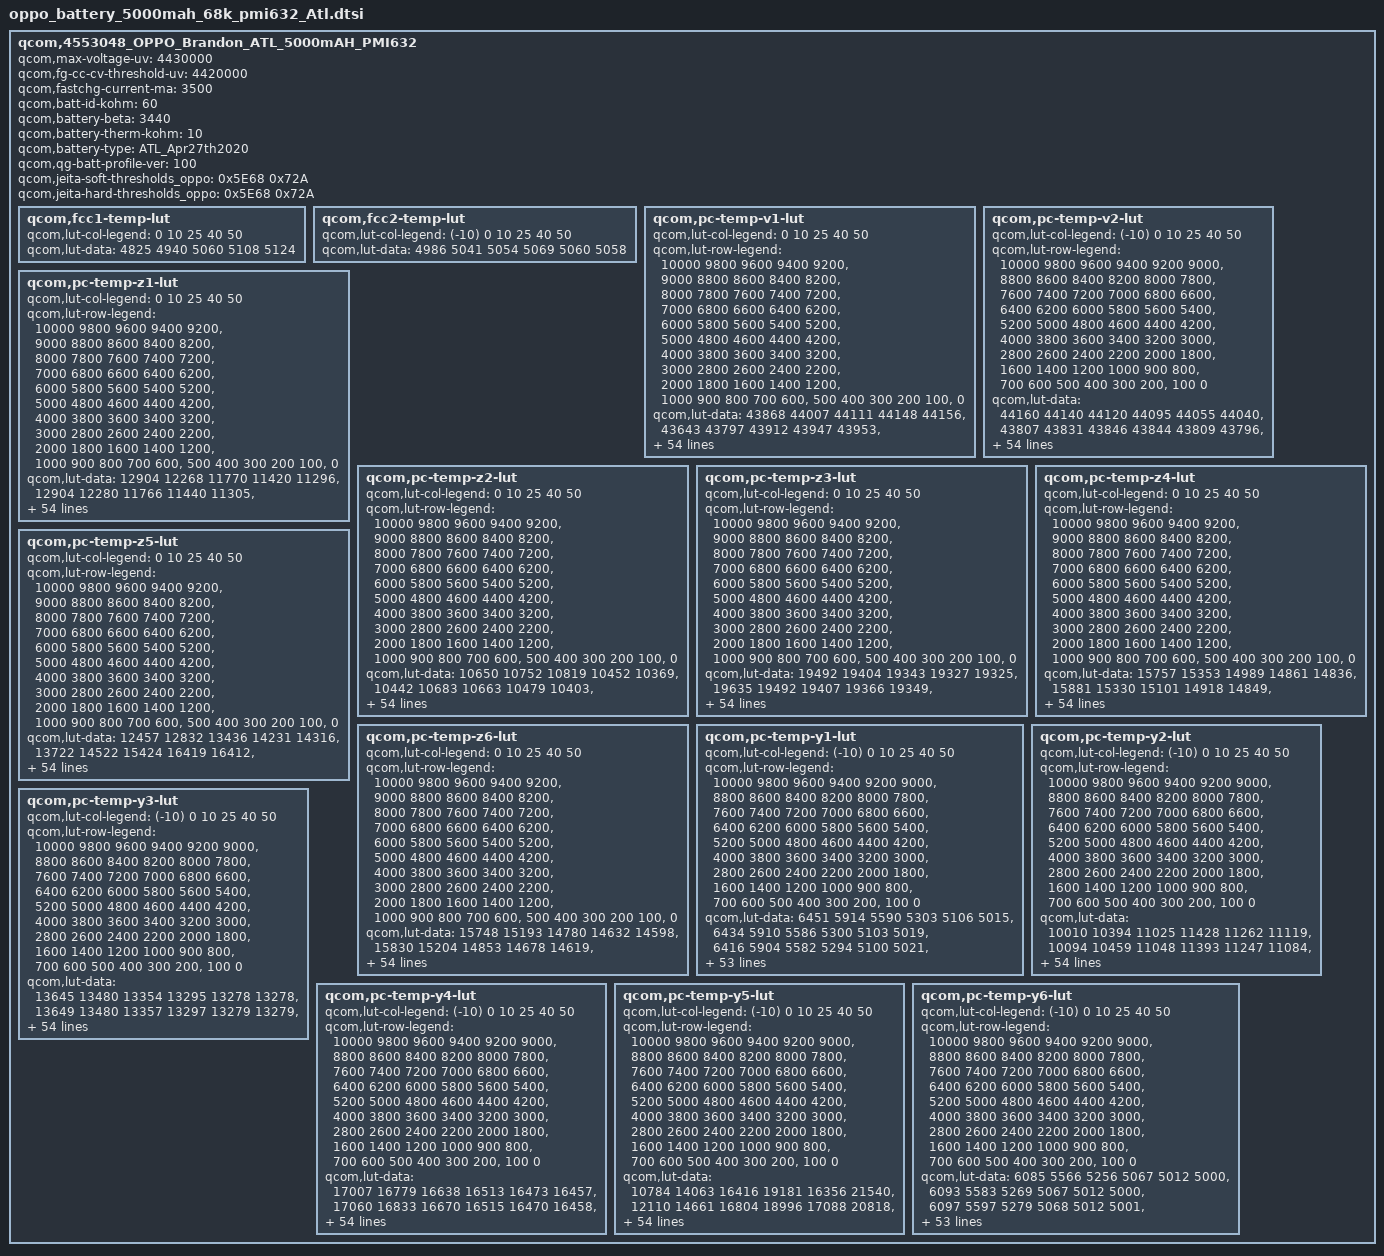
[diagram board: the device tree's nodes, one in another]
qcom,4553048_OPPO_Brandon_ATL_5000mAH_PMI632 {
    /* 4553048_OPPO_Brandon_ATL_5000mAH_PMI632_averaged_MasterSlave_Apr27th2020 */
    qcom,max-voltage-uv = <4430000>;
    qcom,fg-cc-cv-threshold-uv = <4420000>;
    qcom,fastchg-current-ma = <3500>;
    qcom,batt-id-kohm = <60>;
    qcom,battery-beta = <3440>;
    qcom,battery-therm-kohm = <10>;
    qcom,battery-type = "ATL_Apr27th2020";
    qcom,qg-batt-profile-ver = <100>;
    qcom,jeita-soft-thresholds_oppo = <0x5E68 0x72A>;
    qcom,jeita-hard-thresholds_oppo = <0x5E68 0x72A>;

	qcom,fcc1-temp-lut {
		qcom,lut-col-legend = <0 10 25 40 50>;
		qcom,lut-data = <4825 4940 5060 5108 5124>;
	};

	qcom,fcc2-temp-lut {
		qcom,lut-col-legend = <(-10) 0 10 25 40 50>;
		qcom,lut-data = <4986 5041 5054 5069 5060 5058>;
	};

	qcom,pc-temp-v1-lut {
		qcom,lut-col-legend = <0 10 25 40 50>;
		qcom,lut-row-legend = <10000 9800 9600 9400 9200>,
			<9000 8800 8600 8400 8200>,
			<8000 7800 7600 7400 7200>,
			<7000 6800 6600 6400 6200>,
			<6000 5800 5600 5400 5200>,
			<5000 4800 4600 4400 4200>,
			<4000 3800 3600 3400 3200>,
			<3000 2800 2600 2400 2200>,
			<2000 1800 1600 1400 1200>,
			<1000 900 800 700 600>,
			<500 400 300 200 100>,
			<0>;
		qcom,lut-data = <43868 44007 44111 44148 44156>,
			<43643 43797 43912 43947 43953>,
			<43414 43579 43711 43747 43756>,
			<43182 43353 43505 43541 43548>,
			<42950 43122 43280 43326 43332>,
			<42715 42887 43042 43100 43110>,
			<42481 42650 42806 42869 42881>,
			<42249 42412 42567 42633 42647>,
			<42019 42177 42328 42394 42408>,
			<41795 41944 42090 42156 42171>,
			<41575 41718 41855 41920 41935>,
			<41361 41497 41624 41687 41702>,
			<41154 41281 41397 41457 41474>,
			<40954 41074 41177 41231 41250>,
			<40754 40872 40966 41016 41031>,
			<40552 40672 40763 40809 40818>,
			<40355 40472 40566 40609 40614>,
			<40175 40282 40374 40416 40419>,
			<40006 40112 40189 40229 40232>,
			<39845 39954 40022 40053 40055>,
			<39696 39779 39850 39883 39887>,
			<39551 39580 39616 39679 39692>,
			<39396 39373 39314 39403 39430>,
			<39227 39151 39092 39159 39187>,
			<39061 38925 38966 39011 39034>,
			<38898 38781 38867 38896 38916>,
			<38744 38699 38771 38788 38803>,
			<38635 38634 38685 38687 38697>,
			<38562 38567 38602 38592 38596>,
			<38502 38503 38523 38497 38496>,
			<38446 38444 38449 38408 38402>,
			<38396 38386 38380 38329 38319>,
			<38351 38334 38316 38259 38246>,
			<38310 38288 38258 38194 38177>,
			<38273 38249 38207 38134 38110>,
			<38237 38209 38158 38077 38044>,
			<38205 38170 38111 38019 37978>,
			<38166 38126 38066 37963 37912>,
			<38101 38058 38003 37893 37833>,
			<38009 37959 37906 37798 37733>,
			<37905 37848 37791 37687 37619>,
			<37778 37727 37669 37571 37497>,
			<37634 37589 37530 37440 37363>,
			<37469 37418 37365 37280 37203>,
			<37329 37267 37213 37134 37064>,
			<37223 37158 37112 37044 36984>,
			<37192 37129 37080 37015 36954>,
			<37153 37101 37063 36994 36936>,
			<37118 37074 37039 36975 36914>,
			<37075 37041 36987 36913 36841>,
			<36884 36827 36746 36645 36555>,
			<36449 36405 36310 36205 36111>,
			<35872 35837 35735 35629 35536>,
			<35083 35057 34953 34849 34754>,
			<33802 33828 33739 33636 33535>,
			<30000 30000 30000 30000 30000>;
	};

	qcom,pc-temp-v2-lut {
		qcom,lut-col-legend = <(-10) 0 10 25 40 50>;
		qcom,lut-row-legend = <10000 9800 9600 9400 9200 9000>,
			<8800 8600 8400 8200 8000 7800>,
			<7600 7400 7200 7000 6800 6600>,
			<6400 6200 6000 5800 5600 5400>,
			<5200 5000 4800 4600 4400 4200>,
			<4000 3800 3600 3400 3200 3000>,
			<2800 2600 2400 2200 2000 1800>,
			<1600 1400 1200 1000 900 800>,
			<700 600 500 400 300 200>,
			<100 0>;
		qcom,lut-data = <44160 44140 44120 44095 44055 44040>,
			<43807 43831 43846 43844 43809 43796>,
			<43484 43544 43585 43602 43571 43560>,
			<43198 43283 43339 43369 43341 43331>,
			<42946 43046 43112 43146 43120 43111>,
			<42700 42811 42881 42920 42895 42887>,
			<42448 42567 42639 42684 42661 42654>,
			<42197 42322 42394 42444 42422 42417>,
			<41941 42078 42151 42206 42185 42181>,
			<41674 41834 41907 41966 41948 41944>,
			<41442 41589 41670 41731 41715 41711>,
			<41283 41323 41439 41499 41484 41481>,
			<41140 41074 41215 41272 41258 41255>,
			<40915 40906 41001 41052 41040 41036>,
			<40554 40788 40794 40837 40826 40820>,
			<40203 40633 40589 40630 40621 40614>,
			<39934 40355 40388 40428 40422 40416>,
			<39695 40034 40185 40233 40230 40225>,
			<39474 39780 39963 40050 40049 40045>,
			<39271 39557 39725 39874 39874 39874>,
			<39078 39341 39493 39671 39676 39679>,
			<38882 39125 39265 39408 39422 39431>,
			<38698 38916 39053 39154 39174 39186>,
			<38554 38713 38872 38967 38989 39001>,
			<38438 38514 38713 38809 38832 38843>,
			<38342 38360 38570 38672 38697 38707>,
			<38265 38242 38442 38552 38579 38588>,
			<38200 38148 38324 38443 38473 38481>,
			<38136 38083 38206 38341 38376 38381>,
			<38074 38033 38094 38246 38286 38288>,
			<38014 37984 38005 38159 38204 38204>,
			<37954 37936 37935 38080 38130 38129>,
			<37895 37888 37878 38006 38058 38055>,
			<37834 37839 37836 37936 37985 37980>,
			<37773 37789 37803 37868 37911 37902>,
			<37708 37737 37763 37797 37825 37808>,
			<37639 37681 37721 37723 37723 37691>,
			<37564 37620 37670 37646 37619 37576>,
			<37484 37547 37599 37569 37525 37481>,
			<37395 37463 37509 37488 37434 37391>,
			<37305 37369 37406 37400 37342 37298>,
			<37218 37260 37282 37301 37250 37203>,
			<37133 37134 37145 37178 37134 37082>,
			<37051 36986 36994 37038 36996 36941>,
			<36971 36848 36851 36914 36891 36836>,
			<36888 36757 36752 36858 36846 36799>,
			<36838 36723 36720 36837 36836 36787>,
			<36788 36690 36679 36816 36821 36771>,
			<36733 36652 36626 36777 36790 36740>,
			<36662 36590 36527 36687 36702 36639>,
			<36546 36408 36317 36409 36390 36292>,
			<36325 35982 35880 35894 35895 35798>,
			<35918 35316 35265 35236 35256 35147>,
			<35251 34296 34378 34296 34368 34253>,
			<34202 32520 32883 32955 33025 32854>,
			<32670 29515 29418 28130 28230 28273>;
	};

	qcom,pc-temp-z1-lut {
		qcom,lut-col-legend = <0 10 25 40 50>;
		qcom,lut-row-legend = <10000 9800 9600 9400 9200>,
			<9000 8800 8600 8400 8200>,
			<8000 7800 7600 7400 7200>,
			<7000 6800 6600 6400 6200>,
			<6000 5800 5600 5400 5200>,
			<5000 4800 4600 4400 4200>,
			<4000 3800 3600 3400 3200>,
			<3000 2800 2600 2400 2200>,
			<2000 1800 1600 1400 1200>,
			<1000 900 800 700 600>,
			<500 400 300 200 100>,
			<0>;
		qcom,lut-data = <12904 12268 11770 11420 11296>,
			<12904 12280 11766 11440 11305>,
			<12913 12283 11759 11435 11305>,
			<12924 12277 11751 11427 11304>,
			<12924 12267 11744 11420 11302>,
			<12922 12254 11734 11413 11298>,
			<12919 12236 11725 11407 11294>,
			<12904 12219 11715 11401 11291>,
			<12879 12210 11706 11395 11289>,
			<12862 12202 11695 11392 11289>,
			<12846 12193 11686 11390 11289>,
			<12832 12178 11684 11389 11289>,
			<12820 12168 11684 11389 11289>,
			<12803 12165 11684 11389 11289>,
			<12795 12161 11685 11389 11290>,
			<12799 12160 11685 11389 11290>,
			<12803 12159 11685 11390 11291>,
			<12797 12158 11683 11391 11293>,
			<12779 12157 11683 11393 11295>,
			<12762 12157 11686 11395 11297>,
			<12749 12160 11690 11397 11298>,
			<12738 12169 11692 11398 11299>,
			<12738 12178 11696 11400 11300>,
			<12756 12183 11698 11401 11301>,
			<12772 12191 11699 11403 11303>,
			<12779 12193 11702 11406 11307>,
			<12785 12192 11705 11409 11310>,
			<12786 12190 11710 11413 11313>,
			<12787 12193 11714 11417 11316>,
			<12790 12198 11717 11421 11320>,
			<12794 12201 11720 11424 11324>,
			<12798 12202 11725 11428 11328>,
			<12801 12203 11732 11434 11332>,
			<12805 12207 11737 11440 11335>,
			<12808 12215 11740 11444 11340>,
			<12812 12221 11743 11448 11344>,
			<12826 12225 11748 11452 11348>,
			<12837 12229 11754 11456 11352>,
			<12847 12234 11761 11460 11355>,
			<12864 12241 11770 11465 11359>,
			<12876 12250 11778 11470 11362>,
			<12900 12268 11785 11474 11365>,
			<12908 12282 11793 11479 11368>,
			<12891 12293 11807 11484 11371>,
			<12890 12294 11819 11491 11375>,
			<12898 12297 11827 11495 11378>,
			<12908 12281 11819 11496 11378>,
			<12953 12277 11818 11497 11379>,
			<12948 12285 11832 11499 11381>,
			<12908 12298 11842 11504 11385>,
			<12950 12304 11842 11511 11390>,
			<12955 12334 11849 11518 11396>,
			<12986 12338 11866 11530 11405>,
			<13023 12383 11891 11546 11418>,
			<13023 12383 11891 11546 11418>,
			<13023 12383 11891 11546 11418>;
	};

	qcom,pc-temp-z2-lut {
		qcom,lut-col-legend = <0 10 25 40 50>;
		qcom,lut-row-legend = <10000 9800 9600 9400 9200>,
			<9000 8800 8600 8400 8200>,
			<8000 7800 7600 7400 7200>,
			<7000 6800 6600 6400 6200>,
			<6000 5800 5600 5400 5200>,
			<5000 4800 4600 4400 4200>,
			<4000 3800 3600 3400 3200>,
			<3000 2800 2600 2400 2200>,
			<2000 1800 1600 1400 1200>,
			<1000 900 800 700 600>,
			<500 400 300 200 100>,
			<0>;
		qcom,lut-data = <10650 10752 10819 10452 10369>,
			<10442 10683 10663 10479 10403>,
			<10412 10628 11155 10533 10433>,
			<10395 10586 11549 10610 10535>,
			<10375 10550 11287 10623 10569>,
			<10355 10518 10768 10594 10548>,
			<10341 10488 10600 10559 10521>,
			<10332 10463 10559 10522 10487>,
			<10325 10443 10533 10487 10440>,
			<10321 10426 10514 10473 10416>,
			<10318 10424 10501 10461 10402>,
			<10316 10426 10501 10457 10396>,
			<10318 10429 10513 10460 10403>,
			<10323 10447 10531 10462 10411>,
			<10325 10478 10713 10448 10405>,
			<10323 10502 10966 10414 10377>,
			<10321 10517 10958 10389 10363>,
			<10327 10533 10728 10371 10349>,
			<10351 10552 10603 10361 10333>,
			<10377 10571 10615 10370 10341>,
			<10403 10589 10637 10403 10360>,
			<10429 10609 10679 10451 10386>,
			<10443 10623 10754 10553 10458>,
			<10451 10628 10785 10624 10521>,
			<10458 10631 10709 10574 10522>,
			<10471 10632 10620 10477 10508>,
			<10486 10622 10624 10462 10497>,
			<10496 10612 10668 10514 10488>,
			<10502 10613 10705 10570 10484>,
			<10508 10620 10734 10637 10513>,
			<10514 10628 10753 10707 10564>,
			<10522 10639 10751 10705 10557>,
			<10530 10649 10744 10652 10469>,
			<10538 10654 10740 10618 10401>,
			<10547 10657 10740 10613 10375>,
			<10557 10660 10742 10613 10358>,
			<10568 10667 10743 10629 10373>,
			<10581 10677 10748 10672 10438>,
			<10594 10689 10758 10713 10498>,
			<10608 10706 10799 10754 10545>,
			<10623 10716 10833 10782 10581>,
			<10638 10720 10834 10779 10604>,
			<10665 10724 10826 10767 10626>,
			<10730 10746 10814 10777 10681>,
			<10550 10932 10859 10758 10674>,
			<10719 11035 10907 10682 10533>,
			<10241 11044 10900 10638 10522>,
			<10297 11066 10865 10612 10539>,
			<10363 11095 10853 10646 10577>,
			<10048 11232 10908 10779 10672>,
			<10110 11153 11011 10653 10508>,
			<9758 11095 10931 10499 10307>,
			<9832 10908 10879 10394 10249>,
			<9855 10664 10796 10386 10193>,
			<9855 10664 10796 10386 10193>,
			<9855 10664 10796 10386 10193>;
	};

	qcom,pc-temp-z3-lut {
		qcom,lut-col-legend = <0 10 25 40 50>;
		qcom,lut-row-legend = <10000 9800 9600 9400 9200>,
			<9000 8800 8600 8400 8200>,
			<8000 7800 7600 7400 7200>,
			<7000 6800 6600 6400 6200>,
			<6000 5800 5600 5400 5200>,
			<5000 4800 4600 4400 4200>,
			<4000 3800 3600 3400 3200>,
			<3000 2800 2600 2400 2200>,
			<2000 1800 1600 1400 1200>,
			<1000 900 800 700 600>,
			<500 400 300 200 100>,
			<0>;
		qcom,lut-data = <19492 19404 19343 19327 19325>,
			<19635 19492 19407 19366 19349>,
			<19704 19548 19428 19384 19362>,
			<19746 19578 19440 19397 19382>,
			<19762 19596 19454 19406 19394>,
			<19771 19600 19466 19413 19400>,
			<19776 19600 19469 19417 19403>,
			<19777 19600 19467 19418 19405>,
			<19778 19599 19465 19418 19406>,
			<19776 19596 19464 19416 19406>,
			<19769 19591 19462 19409 19401>,
			<19760 19582 19458 19404 19396>,
			<19750 19571 19450 19401 19391>,
			<19737 19560 19445 19398 19387>,
			<19733 19550 19447 19393 19383>,
			<19741 19546 19452 19383 19379>,
			<19749 19544 19448 19377 19375>,
			<19743 19543 19434 19373 19371>,
			<19719 19539 19426 19370 19368>,
			<19701 19531 19424 19368 19363>,
			<19695 19530 19423 19365 19356>,
			<19691 19542 19427 19366 19354>,
			<19693 19555 19442 19372 19355>,
			<19708 19559 19449 19378 19357>,
			<19721 19562 19436 19370 19350>,
			<19723 19562 19420 19354 19336>,
			<19724 19555 19418 19350 19333>,
			<19724 19547 19417 19352 19344>,
			<19716 19544 19417 19355 19358>,
			<19705 19542 19425 19373 19374>,
			<19697 19542 19435 19396 19390>,
			<19691 19543 19439 19399 19392>,
			<19686 19545 19443 19398 19385>,
			<19681 19545 19444 19395 19376>,
			<19675 19542 19441 19389 19368>,
			<19668 19539 19437 19382 19361>,
			<19658 19537 19432 19376 19355>,
			<19649 19535 19426 19371 19351>,
			<19645 19532 19422 19367 19348>,
			<19642 19528 19420 19365 19346>,
			<19636 19524 19418 19363 19344>,
			<19625 19517 19416 19363 19346>,
			<19609 19509 19413 19363 19353>,
			<19587 19499 19408 19363 19357>,
			<19424 19460 19395 19361 19357>,
			<19366 19440 19384 19346 19338>,
			<19295 19424 19384 19344 19336>,
			<19297 19422 19375 19342 19330>,
			<19310 19411 19375 19334 19322>,
			<19267 19311 19368 19326 19321>,
			<19287 19402 19360 19345 19348>,
			<19274 19322 19360 19361 19358>,
			<19302 19309 19366 19365 19359>,
			<19339 19312 19363 19353 19352>,
			<19339 19312 19363 19353 19352>,
			<19339 19312 19363 19353 19352>;
	};

	qcom,pc-temp-z4-lut {
		qcom,lut-col-legend = <0 10 25 40 50>;
		qcom,lut-row-legend = <10000 9800 9600 9400 9200>,
			<9000 8800 8600 8400 8200>,
			<8000 7800 7600 7400 7200>,
			<7000 6800 6600 6400 6200>,
			<6000 5800 5600 5400 5200>,
			<5000 4800 4600 4400 4200>,
			<4000 3800 3600 3400 3200>,
			<3000 2800 2600 2400 2200>,
			<2000 1800 1600 1400 1200>,
			<1000 900 800 700 600>,
			<500 400 300 200 100>,
			<0>;
		qcom,lut-data = <15757 15353 14989 14861 14836>,
			<15881 15330 15101 14918 14849>,
			<15776 15292 15049 14908 14852>,
			<15611 15216 14987 14875 14834>,
			<15484 15113 14945 14846 14814>,
			<15368 15037 14907 14819 14793>,
			<15270 14978 14872 14795 14773>,
			<15189 14929 14842 14774 14755>,
			<15120 14890 14815 14756 14739>,
			<15065 14857 14790 14740 14726>,
			<15020 14832 14768 14726 14714>,
			<14983 14812 14752 14716 14706>,
			<14955 14795 14740 14708 14700>,
			<14931 14778 14729 14702 14696>,
			<14906 14763 14710 14699 14692>,
			<14873 14755 14691 14698 14687>,
			<14848 14752 14690 14695 14683>,
			<14841 14749 14700 14690 14679>,
			<14839 14741 14705 14685 14675>,
			<14835 14732 14702 14683 14675>,
			<14815 14730 14699 14681 14676>,
			<14789 14737 14718 14687 14680>,
			<14782 14749 14788 14746 14735>,
			<14781 14781 14829 14800 14792>,
			<14781 14834 14838 14812 14802>,
			<14795 14852 14842 14819 14808>,
			<14823 14842 14838 14818 14806>,
			<14832 14827 14823 14804 14783>,
			<14830 14815 14805 14784 14752>,
			<14826 14803 14785 14754 14723>,
			<14821 14791 14764 14719 14695>,
			<14813 14780 14749 14703 14685>,
			<14805 14769 14737 14694 14680>,
			<14798 14761 14731 14690 14678>,
			<14791 14755 14728 14690 14678>,
			<14784 14749 14726 14690 14679>,
			<14777 14744 14725 14691 14680>,
			<14770 14740 14724 14692 14682>,
			<14761 14739 14724 14695 14684>,
			<14752 14740 14729 14705 14696>,
			<14748 14740 14732 14714 14707>,
			<14746 14732 14726 14711 14703>,
			<14743 14721 14714 14703 14693>,
			<14734 14713 14710 14700 14691>,
			<14817 14694 14694 14690 14683>,
			<14845 14681 14671 14674 14671>,
			<14921 14689 14663 14668 14666>,
			<14917 14685 14657 14656 14657>,
			<14901 14689 14645 14644 14642>,
			<14933 14796 14649 14646 14635>,
			<14912 14698 14674 14659 14649>,
			<14946 14799 14683 14654 14652>,
			<14932 14818 14679 14655 14655>,
			<14917 14823 14683 14669 14664>,
			<14917 14823 14683 14669 14664>,
			<14917 14823 14683 14669 14664>;
	};

	qcom,pc-temp-z5-lut {
		qcom,lut-col-legend = <0 10 25 40 50>;
		qcom,lut-row-legend = <10000 9800 9600 9400 9200>,
			<9000 8800 8600 8400 8200>,
			<8000 7800 7600 7400 7200>,
			<7000 6800 6600 6400 6200>,
			<6000 5800 5600 5400 5200>,
			<5000 4800 4600 4400 4200>,
			<4000 3800 3600 3400 3200>,
			<3000 2800 2600 2400 2200>,
			<2000 1800 1600 1400 1200>,
			<1000 900 800 700 600>,
			<500 400 300 200 100>,
			<0>;
		qcom,lut-data = <12457 12832 13436 14231 14316>,
			<13722 14522 15424 16419 16412>,
			<14431 15830 16066 17472 17161>,
			<14960 16749 16480 18406 19269>,
			<15398 17487 17256 19214 20710>,
			<15744 18149 18320 19965 21471>,
			<16110 18723 18835 20465 22167>,
			<16629 19326 19168 21016 23054>,
			<17224 20135 19560 21622 23972>,
			<17706 20949 20202 21855 24728>,
			<18184 21424 21058 22278 25546>,
			<18537 21742 21833 22696 26067>,
			<18744 22097 22522 23609 26196>,
			<19024 22671 23412 24546 26297>,
			<19549 23454 26108 24259 26649>,
			<21824 24406 29215 23041 27570>,
			<24082 25915 29348 22558 28509>,
			<24020 27137 27804 23134 29650>,
			<22984 27309 26954 23975 30595>,
			<22416 27215 27729 24660 30365>,
			<23460 28531 29503 25444 29357>,
			<25809 38077 33729 26585 28946>,
			<29642 46694 42928 28960 28157>,
			<38348 47241 46951 30601 26763>,
			<45826 46715 38496 27205 23439>,
			<48858 45394 27802 20479 18180>,
			<51050 39805 24895 18241 16777>,
			<51318 34243 23492 17657 17149>,
			<47477 32754 23157 17444 17859>,
			<42755 31934 24582 19959 21416>,
			<40477 31796 27023 24655 26980>,
			<38863 33589 30015 28008 28953>,
			<37893 36054 33925 30892 29733>,
			<37303 37486 36831 32473 30040>,
			<36728 38573 39125 33153 29790>,
			<35886 39613 40441 33552 29360>,
			<34286 40906 39876 33359 29126>,
			<33292 41874 38170 32420 28800>,
			<34413 41930 36661 31222 28233>,
			<36481 41725 35255 29319 25967>,
			<36843 41334 34025 27354 23803>,
			<34563 38661 33209 25997 24014>,
			<32580 35994 32354 25112 25061>,
			<30816 35130 30226 25453 26961>,
			<21517 32333 30177 25797 27840>,
			<16113 31277 30542 23094 22090>,
			<12460 24700 31543 22984 21412>,
			<12455 23766 27667 24259 20815>,
			<12607 22019 29841 23744 22512>,
			<11939 13240 26835 21495 23364>,
			<12308 20595 20910 22182 26315>,
			<11953 13391 18851 24243 25270>,
			<12217 12728 19184 23646 22851>,
			<12515 12605 18363 18160 18332>,
			<12515 12605 18363 18160 18332>,
			<12515 12605 18363 18160 18332>;
	};

	qcom,pc-temp-z6-lut {
		qcom,lut-col-legend = <0 10 25 40 50>;
		qcom,lut-row-legend = <10000 9800 9600 9400 9200>,
			<9000 8800 8600 8400 8200>,
			<8000 7800 7600 7400 7200>,
			<7000 6800 6600 6400 6200>,
			<6000 5800 5600 5400 5200>,
			<5000 4800 4600 4400 4200>,
			<4000 3800 3600 3400 3200>,
			<3000 2800 2600 2400 2200>,
			<2000 1800 1600 1400 1200>,
			<1000 900 800 700 600>,
			<500 400 300 200 100>,
			<0>;
		qcom,lut-data = <15748 15193 14780 14632 14598>,
			<15830 15204 14853 14678 14619>,
			<15782 15203 14837 14678 14625>,
			<15704 15173 14818 14673 14628>,
			<15637 15119 14803 14667 14628>,
			<15570 15077 14788 14658 14622>,
			<15509 15041 14772 14649 14615>,
			<15460 15009 14755 14640 14608>,
			<15416 14983 14739 14631 14602>,
			<15378 14961 14726 14622 14596>,
			<15346 14940 14713 14613 14588>,
			<15317 14920 14702 14605 14582>,
			<15291 14903 14692 14600 14576>,
			<15268 14888 14684 14596 14572>,
			<15249 14874 14678 14591 14567>,
			<15234 14867 14673 14585 14563>,
			<15221 14863 14669 14580 14559>,
			<15206 14860 14666 14576 14555>,
			<15190 14854 14663 14572 14552>,
			<15176 14847 14662 14570 14548>,
			<15161 14846 14660 14568 14546>,
			<15148 14855 14671 14571 14546>,
			<15147 14870 14711 14602 14572>,
			<15155 14890 14731 14627 14597>,
			<15166 14916 14729 14626 14597>,
			<15178 14924 14724 14624 14594>,
			<15191 14917 14720 14621 14591>,
			<15195 14908 14714 14616 14587>,
			<15192 14902 14710 14612 14583>,
			<15187 14898 14706 14609 14580>,
			<15183 14895 14703 14606 14578>,
			<15178 14892 14700 14603 14574>,
			<15174 14889 14698 14599 14569>,
			<15171 14887 14696 14595 14564>,
			<15169 14884 14695 14592 14560>,
			<15165 14883 14693 14589 14557>,
			<15160 14883 14691 14587 14555>,
			<15158 14883 14689 14586 14554>,
			<15159 14884 14689 14585 14553>,
			<15162 14888 14692 14589 14557>,
			<15164 14889 14694 14593 14561>,
			<15166 14888 14693 14591 14561>,
			<15167 14885 14689 14588 14561>,
			<15164 14884 14687 14588 14562>,
			<15133 14868 14679 14584 14560>,
			<15122 14857 14666 14570 14545>,
			<15121 14853 14663 14567 14542>,
			<15120 14852 14657 14560 14534>,
			<15122 14850 14653 14551 14524>,
			<15124 14849 14653 14549 14521>,
			<15132 14860 14664 14566 14542>,
			<15148 14869 14670 14574 14551>,
			<15169 14879 14677 14579 14556>,
			<15200 14897 14683 14583 14559>,
			<15200 14897 14683 14583 14559>,
			<15200 14897 14683 14583 14559>;
	};

	qcom,pc-temp-y1-lut {
		qcom,lut-col-legend = <(-10) 0 10 25 40 50>;
		qcom,lut-row-legend = <10000 9800 9600 9400 9200 9000>,
			<8800 8600 8400 8200 8000 7800>,
			<7600 7400 7200 7000 6800 6600>,
			<6400 6200 6000 5800 5600 5400>,
			<5200 5000 4800 4600 4400 4200>,
			<4000 3800 3600 3400 3200 3000>,
			<2800 2600 2400 2200 2000 1800>,
			<1600 1400 1200 1000 900 800>,
			<700 600 500 400 300 200>,
			<100 0>;
		qcom,lut-data = <6451 5914 5590 5303 5106 5015>,
			<6434 5910 5586 5300 5103 5019>,
			<6416 5904 5582 5294 5100 5021>,
			<6400 5897 5577 5287 5098 5023>,
			<6389 5892 5574 5282 5095 5023>,
			<6386 5890 5571 5279 5093 5024>,
			<6390 5891 5569 5279 5091 5022>,
			<6397 5892 5567 5278 5090 5020>,
			<6404 5891 5567 5277 5088 5019>,
			<6415 5888 5569 5273 5086 5019>,
			<6423 5886 5569 5271 5084 5019>,
			<6424 5899 5564 5271 5083 5018>,
			<6422 5915 5557 5271 5082 5017>,
			<6418 5916 5561 5269 5081 5017>,
			<6405 5907 5575 5265 5081 5017>,
			<6396 5903 5581 5264 5081 5017>,
			<6395 5913 5576 5264 5081 5017>,
			<6396 5923 5570 5265 5081 5018>,
			<6398 5922 5567 5265 5082 5018>,
			<6410 5914 5565 5266 5083 5019>,
			<6422 5910 5565 5267 5084 5019>,
			<6432 5911 5570 5269 5085 5020>,
			<6444 5914 5575 5272 5086 5021>,
			<6445 5918 5575 5274 5087 5022>,
			<6435 5928 5573 5276 5089 5025>,
			<6428 5931 5574 5279 5092 5027>,
			<6435 5928 5577 5286 5094 5029>,
			<6450 5923 5582 5292 5096 5031>,
			<6450 5918 5585 5295 5098 5033>,
			<6425 5910 5590 5297 5100 5034>,
			<6406 5908 5591 5299 5102 5036>,
			<6410 5919 5593 5302 5107 5039>,
			<6420 5929 5596 5306 5112 5042>,
			<6419 5928 5596 5309 5116 5045>,
			<6404 5922 5596 5312 5120 5047>,
			<6392 5921 5596 5315 5123 5049>,
			<6396 5927 5597 5317 5126 5051>,
			<6405 5933 5599 5319 5128 5052>,
			<6409 5937 5600 5323 5130 5054>,
			<6411 5942 5602 5327 5131 5056>,
			<6411 5942 5605 5335 5133 5057>,
			<6415 5932 5616 5347 5135 5058>,
			<6419 5929 5618 5347 5137 5060>,
			<6422 5941 5610 5344 5138 5062>,
			<6438 5962 5612 5355 5141 5066>,
			<6439 5965 5626 5352 5144 5067>,
			<6487 5974 5625 5355 5146 5067>,
			<6494 5976 5623 5356 5144 5066>,
			<6498 5976 5629 5359 5145 5067>,
			<6518 6012 5646 5363 5146 5067>,
			<6603 6030 5661 5369 5145 5069>,
			<6668 6065 5666 5386 5152 5074>,
			<6738 6135 5720 5405 5158 5080>,
			<6848 6237 5756 5416 5171 5089>,
			<6848 6237 5756 5416 5171 5089>,
			<6848 6237 5756 5416 5171 5089>;
	};

	qcom,pc-temp-y2-lut {
		qcom,lut-col-legend = <(-10) 0 10 25 40 50>;
		qcom,lut-row-legend = <10000 9800 9600 9400 9200 9000>,
			<8800 8600 8400 8200 8000 7800>,
			<7600 7400 7200 7000 6800 6600>,
			<6400 6200 6000 5800 5600 5400>,
			<5200 5000 4800 4600 4400 4200>,
			<4000 3800 3600 3400 3200 3000>,
			<2800 2600 2400 2200 2000 1800>,
			<1600 1400 1200 1000 900 800>,
			<700 600 500 400 300 200>,
			<100 0>;
		qcom,lut-data = <10010 10394 11025 11428 11262 11119>,
			<10094 10459 11048 11393 11247 11084>,
			<10174 10528 11065 11358 11195 11049>,
			<10248 10593 11076 11326 11130 11015>,
			<10314 10648 11082 11297 11072 10984>,
			<10369 10685 11083 11274 11042 10956>,
			<10407 10711 11072 11257 11021 10927>,
			<10442 10728 11056 11241 11002 10903>,
			<10520 10724 11050 11223 11014 10893>,
			<10698 10696 11046 11203 11057 10886>,
			<10807 10683 11045 11195 11077 10884>,
			<10791 10797 11047 11205 11044 10875>,
			<10745 10945 11052 11221 11004 10864>,
			<10598 10955 11082 11235 11010 10869>,
			<10068 10919 11179 11251 11049 10892>,
			<9706 10903 11260 11274 11087 10914>,
			<9691 10980 11316 11320 11143 10934>,
			<9685 11091 11355 11382 11213 10961>,
			<9680 11151 11369 11465 11289 11038>,
			<9677 11195 11378 11566 11380 11192>,
			<9675 11209 11379 11594 11409 11250>,
			<9673 11186 11366 11535 11373 11230>,
			<9672 11136 11354 11475 11331 11207>,
			<9671 10963 11367 11470 11308 11198>,
			<9670 10550 11403 11477 11277 11192>,
			<9669 10291 11421 11490 11273 11200>,
			<9668 9993 11426 11525 11345 11228>,
			<9667 9729 11428 11565 11421 11266>,
			<9666 9700 11418 11592 11441 11315>,
			<9666 9692 11391 11617 11455 11376>,
			<9666 9687 11367 11647 11476 11398>,
			<9665 9682 11345 11685 11523 11392>,
			<9665 9678 11318 11707 11565 11389>,
			<9664 9674 11272 11685 11597 11451>,
			<9664 9670 11204 11646 11631 11559>,
			<9664 9668 11133 11636 11633 11570>,
			<9664 9666 11065 11636 11585 11449>,
			<9663 9665 10962 11634 11530 11350>,
			<9663 9663 10591 11605 11486 11340>,
			<9662 9662 10028 11553 11449 11346>,
			<9662 9662 9804 11510 11447 11360>,
			<9662 9661 9728 11470 11469 11393>,
			<9662 9661 9696 11404 11458 11358>,
			<9661 9660 9683 11315 11395 11219>,
			<9660 9659 9675 11258 11331 11186>,
			<9659 9659 9672 11243 11150 11017>,
			<9659 9658 9669 11201 11231 10988>,
			<9658 9658 9667 11172 11241 11060>,
			<9656 9657 9664 11176 11253 11086>,
			<9654 9656 9661 11178 11250 11077>,
			<9651 9654 9659 11102 11196 10973>,
			<9649 9651 9657 10990 11103 10880>,
			<9648 9649 9655 10829 11054 10812>,
			<9648 9649 9653 10671 10880 10719>,
			<9648 9649 9653 10671 10880 10719>,
			<9648 9649 9653 10671 10880 10719>;
	};

	qcom,pc-temp-y3-lut {
		qcom,lut-col-legend = <(-10) 0 10 25 40 50>;
		qcom,lut-row-legend = <10000 9800 9600 9400 9200 9000>,
			<8800 8600 8400 8200 8000 7800>,
			<7600 7400 7200 7000 6800 6600>,
			<6400 6200 6000 5800 5600 5400>,
			<5200 5000 4800 4600 4400 4200>,
			<4000 3800 3600 3400 3200 3000>,
			<2800 2600 2400 2200 2000 1800>,
			<1600 1400 1200 1000 900 800>,
			<700 600 500 400 300 200>,
			<100 0>;
		qcom,lut-data = <13645 13480 13354 13295 13278 13278>,
			<13649 13480 13357 13297 13279 13279>,
			<13650 13479 13360 13299 13280 13279>,
			<13647 13479 13363 13300 13282 13280>,
			<13643 13480 13366 13301 13283 13280>,
			<13637 13480 13368 13302 13284 13281>,
			<13628 13481 13369 13304 13284 13282>,
			<13617 13484 13370 13305 13284 13283>,
			<13605 13484 13371 13305 13285 13284>,
			<13594 13481 13371 13305 13286 13284>,
			<13579 13476 13372 13305 13287 13285>,
			<13548 13448 13372 13305 13287 13285>,
			<13512 13414 13372 13305 13287 13285>,
			<13509 13413 13369 13305 13288 13285>,
			<13535 13426 13356 13307 13291 13286>,
			<13553 13433 13350 13308 13293 13286>,
			<13536 13428 13352 13306 13295 13288>,
			<13508 13419 13355 13303 13296 13290>,
			<13502 13410 13354 13304 13296 13291>,
			<13506 13400 13348 13307 13295 13292>,
			<13510 13389 13342 13307 13294 13293>,
			<13513 13377 13337 13303 13289 13288>,
			<13515 13366 13333 13298 13285 13282>,
			<13518 13362 13330 13296 13282 13280>,
			<13524 13360 13327 13295 13281 13279>,
			<13532 13358 13325 13294 13280 13278>,
			<13551 13354 13322 13294 13280 13278>,
			<13583 13350 13320 13294 13280 13278>,
			<13612 13355 13319 13294 13280 13278>,
			<13640 13373 13318 13293 13280 13276>,
			<13670 13393 13316 13293 13280 13276>,
			<13702 13414 13313 13293 13280 13276>,
			<13737 13439 13311 13293 13281 13277>,
			<13774 13472 13313 13292 13281 13278>,
			<13815 13516 13319 13292 13282 13279>,
			<13856 13566 13324 13292 13282 13279>,
			<13896 13624 13327 13292 13281 13278>,
			<13935 13686 13331 13292 13280 13277>,
			<13973 13752 13337 13292 13280 13278>,
			<14009 13820 13346 13292 13280 13279>,
			<14046 13879 13358 13292 13280 13280>,
			<14081 13931 13379 13295 13282 13281>,
			<14118 13977 13403 13296 13282 13281>,
			<14164 14018 13438 13296 13279 13277>,
			<14230 14063 13485 13298 13280 13276>,
			<14265 14089 13500 13300 13283 13283>,
			<14321 14149 13552 13302 13289 13287>,
			<14439 14229 13616 13308 13292 13289>,
			<14626 14343 13707 13314 13294 13291>,
			<15064 14511 13819 13318 13294 13289>,
			<16338 14854 13966 13317 13288 13283>,
			<19419 16196 14175 13318 13288 13286>,
			<27586 20753 14515 13329 13294 13288>,
			<53157 39160 15577 13349 13298 13296>,
			<53157 39160 15577 13349 13298 13296>,
			<53157 39160 15577 13349 13298 13296>;
	};

	qcom,pc-temp-y4-lut {
		qcom,lut-col-legend = <(-10) 0 10 25 40 50>;
		qcom,lut-row-legend = <10000 9800 9600 9400 9200 9000>,
			<8800 8600 8400 8200 8000 7800>,
			<7600 7400 7200 7000 6800 6600>,
			<6400 6200 6000 5800 5600 5400>,
			<5200 5000 4800 4600 4400 4200>,
			<4000 3800 3600 3400 3200 3000>,
			<2800 2600 2400 2200 2000 1800>,
			<1600 1400 1200 1000 900 800>,
			<700 600 500 400 300 200>,
			<100 0>;
		qcom,lut-data = <17007 16779 16638 16513 16473 16457>,
			<17060 16833 16670 16515 16470 16458>,
			<17127 16910 16711 16518 16468 16459>,
			<17194 16991 16753 16521 16468 16460>,
			<17244 17053 16785 16523 16468 16460>,
			<17265 17077 16797 16523 16468 16461>,
			<17260 17071 16793 16523 16470 16460>,
			<17247 17060 16786 16522 16472 16460>,
			<17229 17052 16778 16523 16474 16461>,
			<17198 17044 16769 16527 16476 16463>,
			<17179 17042 16765 16531 16479 16465>,
			<17254 17071 16767 16537 16484 16469>,
			<17377 17122 16771 16545 16490 16473>,
			<17379 17167 16792 16553 16494 16478>,
			<17231 17213 16848 16561 16496 16483>,
			<17099 17231 16874 16573 16501 16488>,
			<17057 17134 16867 16595 16508 16493>,
			<17027 16997 16854 16619 16519 16499>,
			<16988 16936 16830 16639 16539 16513>,
			<16937 16900 16785 16657 16568 16535>,
			<16886 16862 16740 16659 16577 16542>,
			<16828 16815 16691 16599 16540 16517>,
			<16776 16766 16649 16534 16497 16487>,
			<16766 16708 16624 16513 16480 16473>,
			<16769 16644 16606 16499 16470 16464>,
			<16772 16622 16593 16496 16467 16461>,
			<16772 16632 16584 16498 16470 16463>,
			<16771 16645 16574 16500 16474 16466>,
			<16771 16650 16552 16503 16480 16471>,
			<16773 16654 16521 16508 16489 16480>,
			<16775 16659 16513 16513 16498 16489>,
			<16777 16666 16517 16521 16509 16499>,
			<16779 16675 16524 16526 16517 16507>,
			<16781 16684 16535 16526 16519 16510>,
			<16782 16692 16552 16526 16520 16511>,
			<16783 16700 16570 16523 16518 16509>,
			<16784 16708 16591 16507 16499 16493>,
			<16786 16714 16612 16497 16483 16479>,
			<16786 16717 16633 16496 16476 16476>,
			<16785 16719 16651 16496 16472 16475>,
			<16783 16719 16661 16499 16472 16475>,
			<16783 16715 16666 16510 16475 16478>,
			<16783 16709 16666 16518 16473 16475>,
			<16793 16699 16664 16521 16463 16458>,
			<16807 16685 16658 16514 16453 16447>,
			<16784 16669 16651 16513 16464 16462>,
			<16788 16680 16665 16529 16478 16486>,
			<16797 16698 16687 16552 16506 16519>,
			<16810 16720 16724 16584 16538 16549>,
			<16856 16747 16776 16608 16551 16554>,
			<17071 16756 16815 16593 16487 16478>,
			<17622 16927 16825 16566 16473 16469>,
			<19749 18302 16863 16597 16477 16471>,
			<34119 36964 17339 16640 16494 16479>,
			<34119 36964 17339 16640 16494 16479>,
			<34119 36964 17339 16640 16494 16479>;
	};

	qcom,pc-temp-y5-lut {
		qcom,lut-col-legend = <(-10) 0 10 25 40 50>;
		qcom,lut-row-legend = <10000 9800 9600 9400 9200 9000>,
			<8800 8600 8400 8200 8000 7800>,
			<7600 7400 7200 7000 6800 6600>,
			<6400 6200 6000 5800 5600 5400>,
			<5200 5000 4800 4600 4400 4200>,
			<4000 3800 3600 3400 3200 3000>,
			<2800 2600 2400 2200 2000 1800>,
			<1600 1400 1200 1000 900 800>,
			<700 600 500 400 300 200>,
			<100 0>;
		qcom,lut-data = <10784 14063 16416 19181 16356 21540>,
			<12110 14661 16804 18996 17088 20818>,
			<13508 15243 17219 18806 17442 19988>,
			<14841 15808 17616 18613 17521 19198>,
			<15976 16353 17953 18417 17426 18596>,
			<16777 16877 18186 18218 17259 18332>,
			<17317 17498 18358 18038 16841 18416>,
			<17711 18002 18475 17834 16305 18527>,
			<17891 18052 18442 17474 16028 18332>,
			<17997 17943 18238 16862 15863 17850>,
			<18108 17741 18086 16277 15651 17332>,
			<18371 16275 18009 15709 15194 16767>,
			<18691 14496 17895 15280 14780 16182>,
			<18765 15229 17394 15185 14891 15680>,
			<18625 18877 16110 15150 15407 15201>,
			<18376 20745 15573 15083 15641 15034>,
			<17097 20754 17197 14754 15601 15168>,
			<15208 20756 19504 14438 15557 15413>,
			<14872 21047 20850 15217 15620 15692>,
			<15337 21961 21906 17675 15897 16081>,
			<15667 22419 22417 19659 16387 16678>,
			<15273 22456 22606 21265 18117 18175>,
			<14418 22480 22739 22226 19665 19441>,
			<13655 22254 22878 22183 19558 19414>,
			<12826 21302 23011 21993 18975 19075>,
			<12360 20266 23151 21891 18397 18665>,
			<12414 16529 23324 21814 17758 18103>,
			<12537 12971 23489 21707 17293 17435>,
			<12573 12810 23785 21466 17148 16550>,
			<12633 13008 24194 21145 17049 15558>,
			<12713 13155 23796 21114 17070 15320>,
			<12805 13225 20261 21510 17472 15627>,
			<12937 13303 17341 22051 18082 16138>,
			<13101 13474 17668 22775 18951 17246>,
			<13355 13756 18517 23534 20029 18821>,
			<13555 14064 18839 23699 20681 19402>,
			<13642 14484 18922 23623 21133 19525>,
			<13699 14808 18956 23454 21342 19683>,
			<13672 14896 18306 22288 20988 20444>,
			<13433 14946 16936 20494 20392 21575>,
			<13194 14923 16023 19596 20395 22054>,
			<13085 14774 15285 19078 20979 22208>,
			<13005 14507 14880 18322 20557 21813>,
			<12874 14017 14611 17756 19283 20298>,
			<12811 13772 14744 18362 19322 17114>,
			<13010 13703 14370 18622 17821 18583>,
			<12919 13520 14590 17977 19336 18462>,
			<13111 13401 14404 18063 19157 17435>,
			<13327 13495 14442 18305 18425 17017>,
			<13158 13940 14467 18921 18095 16569>,
			<12087 13908 14854 19052 17903 16350>,
			<10670 12145 14095 18999 18191 17573>,
			<9501 9980 13668 18698 20496 17217>,
			<8946 8982 11498 19089 21592 21947>,
			<8946 8982 11498 19089 21592 21947>,
			<8946 8982 11498 19089 21592 21947>;
	};

	qcom,pc-temp-y6-lut {
		qcom,lut-col-legend = <(-10) 0 10 25 40 50>;
		qcom,lut-row-legend = <10000 9800 9600 9400 9200 9000>,
			<8800 8600 8400 8200 8000 7800>,
			<7600 7400 7200 7000 6800 6600>,
			<6400 6200 6000 5800 5600 5400>,
			<5200 5000 4800 4600 4400 4200>,
			<4000 3800 3600 3400 3200 3000>,
			<2800 2600 2400 2200 2000 1800>,
			<1600 1400 1200 1000 900 800>,
			<700 600 500 400 300 200>,
			<100 0>;
		qcom,lut-data = <6085 5566 5256 5067 5012 5000>,
			<6093 5583 5269 5067 5012 5000>,
			<6097 5597 5279 5068 5012 5001>,
			<6097 5609 5286 5069 5013 5001>,
			<6094 5617 5290 5069 5013 5002>,
			<6090 5620 5292 5070 5014 5003>,
			<6081 5617 5289 5070 5015 5003>,
			<6067 5611 5284 5069 5015 5004>,
			<6052 5606 5280 5070 5016 5005>,
			<6033 5599 5274 5070 5017 5006>,
			<6023 5592 5271 5071 5019 5007>,
			<6028 5583 5270 5072 5020 5008>,
			<6036 5575 5269 5074 5021 5009>,
			<6031 5581 5270 5076 5023 5011>,
			<5985 5608 5277 5080 5026 5012>,
			<5939 5621 5279 5084 5029 5014>,
			<5914 5594 5279 5088 5032 5017>,
			<5895 5556 5277 5093 5036 5020>,
			<5884 5538 5271 5099 5042 5025>,
			<5877 5527 5254 5106 5049 5032>,
			<5872 5516 5238 5107 5051 5034>,
			<5866 5504 5221 5087 5037 5023>,
			<5861 5493 5208 5065 5021 5010>,
			<5862 5483 5201 5059 5015 5005>,
			<5874 5474 5197 5054 5011 5001>,
			<5891 5472 5195 5053 5010 5000>,
			<5911 5480 5195 5054 5011 5001>,
			<5936 5494 5194 5056 5012 5002>,
			<5961 5513 5192 5057 5014 5003>,
			<5986 5544 5189 5059 5017 5005>,
			<6013 5576 5189 5061 5020 5007>,
			<6039 5609 5194 5064 5023 5011>,
			<6066 5646 5203 5067 5026 5014>,
			<6097 5688 5217 5068 5028 5016>,
			<6132 5736 5237 5069 5029 5017>,
			<6167 5788 5260 5069 5028 5017>,
			<6199 5846 5285 5066 5023 5011>,
			<6231 5905 5313 5064 5018 5007>,
			<6262 5965 5345 5064 5016 5007>,
			<6293 6025 5380 5066 5015 5008>,
			<6324 6078 5418 5069 5016 5008>,
			<6358 6124 5460 5076 5018 5010>,
			<6395 6165 5507 5082 5018 5009>,
			<6442 6200 5562 5087 5013 5002>,
			<6508 6238 5622 5090 5012 4999>,
			<6545 6260 5644 5093 5017 5009>,
			<6599 6316 5705 5102 5026 5018>,
			<6708 6392 5778 5115 5036 5029>,
			<6881 6494 5874 5131 5046 5039>,
			<7301 6653 5993 5142 5050 5039>,
			<8428 6957 6142 5140 5028 5014>,
			<10939 8111 6332 5139 5024 5013>,
			<17360 11878 6640 5176 5031 5017>,
			<38871 30006 7649 5225 5041 5027>,
			<38871 30006 7649 5225 5041 5027>,
			<38871 30006 7649 5225 5041 5027>;
	};

};
